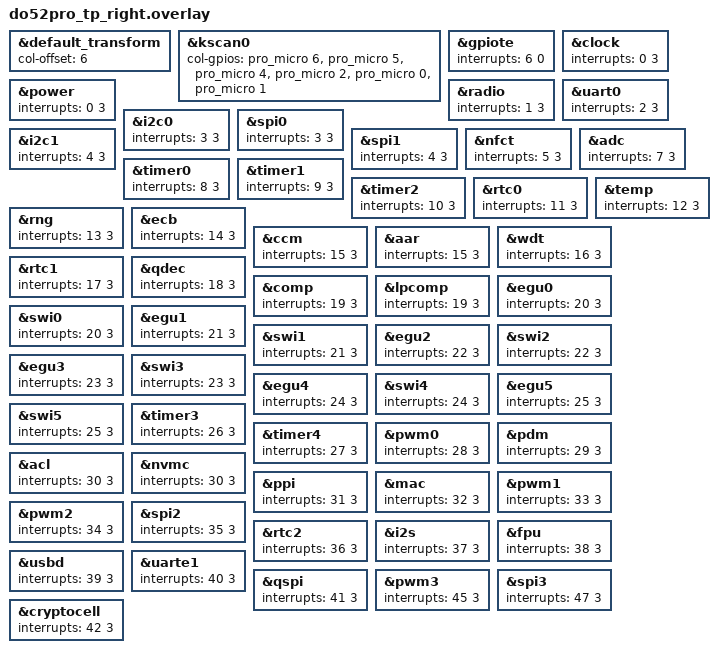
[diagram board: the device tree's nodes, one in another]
#include "do52pro_tp.dtsi"

&default_transform {
    col-offset = <6>;
};

&kscan0 {
    col-gpios
        = <&pro_micro 6 GPIO_ACTIVE_HIGH>
        , <&pro_micro 5 GPIO_ACTIVE_HIGH>
        , <&pro_micro 4 GPIO_ACTIVE_HIGH>
        , <&pro_micro 2 GPIO_ACTIVE_HIGH>
        , <&pro_micro 0 GPIO_ACTIVE_HIGH>
        , <&pro_micro 1 GPIO_ACTIVE_HIGH>
        ;
};

// 安定したUARTドライバーを有効化
#define MOUSE_PS2_DRIVER_UART

// SCL / SDA ピン設定
#define MOUSE_PS2_PIN_SCL_PRO_MICRO <&pro_micro 15 GPIO_ACTIVE_HIGH>
#define MOUSE_PS2_PIN_SDA_PRO_MICRO <&pro_micro 16 GPIO_ACTIVE_HIGH>
#define MOUSE_PS2_PIN_SDA_PINCTRL <NRF_PSEL(UART_RX, 0, 10)>

// リセット回路(2.2uF + 100kR)が基板上にあるため未接続のまま
// #define MOUSE_PS2_PIN_RST_PRO_MICRO <&pro_micro 9 GPIO_ACTIVE_HIGH>

// UARTボーレート設定
#define MOUSE_PS2_UART_BAUD_RATE <14400>

// nice!nano 未露出ピン設定（変更不要）
#define MOUSE_PS2_PIN_UNEXPOSED_TX <NRF_PSEL(UART_TX, 0, 27)>
#define MOUSE_PS2_PIN_UNEXPOSED_RX <NRF_PSEL(UART_RX, 0, 28)>

// 割り込み優先度設定（nice!nano v2用：これがないとUARTが動きません）
&gpiote {
    interrupts = < 6 0 >;
};

&clock {
    interrupts = < 0 3 >;
};

&power {
    interrupts = < 0 3 >;
};

&radio {
    interrupts = < 1 3 >;
};

&uart0 {
    interrupts = < 2 3 >;
};

&i2c0 {
    interrupts = < 3 3 >;
};

&spi0 {
    interrupts = < 3 3 >;
};

&i2c1 {
    interrupts = < 4 3 >;
};

&spi1 {
    interrupts = < 4 3 >;
};

&nfct {
    interrupts = < 5 3 >;
};

&adc {
    interrupts = < 7 3 >;
};

&timer0 {
    interrupts = < 8 3 >;
};

&timer1 {
    interrupts = < 9 3 >;
};

&timer2 {
    interrupts = < 10 3 >;
};

&rtc0 {
    interrupts = < 11 3 >;
};

&temp {
    interrupts = < 12 3 >;
};

&rng {
    interrupts = < 13 3 >;
};

&ecb {
    interrupts = < 14 3 >;
};

&ccm {
    interrupts = < 15 3 >;
};

&aar {
    interrupts = < 15 3 >;
};

&wdt {
    interrupts = < 16 3 >;
};

&rtc1 {
    interrupts = < 17 3 >;
};

&qdec {
    interrupts = < 18 3 >;
};

&comp {
    interrupts = < 19 3 >;
};

&lpcomp {
    interrupts = < 19 3 >;
};

&egu0 {
    interrupts = < 20 3 >;
};

&swi0 {
    interrupts = < 20 3 >;
};

&egu1 {
    interrupts = < 21 3 >;
};

&swi1 {
    interrupts = < 21 3 >;
};

&egu2 {
    interrupts = < 22 3 >;
};

&swi2 {
    interrupts = < 22 3 >;
};

&egu3 {
    interrupts = < 23 3 >;
};

&swi3 {
    interrupts = < 23 3 >;
};

&egu4 {
    interrupts = < 24 3 >;
};

&swi4 {
    interrupts = < 24 3 >;
};

&egu5 {
    interrupts = < 25 3 >;
};

&swi5 {
    interrupts = < 25 3 >;
};

&timer3 {
    interrupts = < 26 3 >;
};

&timer4 {
    interrupts = < 27 3 >;
};

&pwm0 {
    interrupts = < 28 3 >;
};

&pdm {
    interrupts = < 29 3 >;
};

&acl {
    interrupts = < 30 3 >;
};

&nvmc {
    interrupts = < 30 3 >;
};

&ppi {
    interrupts = < 31 3 >;
};

&mac {
    interrupts = < 32 3 >;
};

&pwm1 {
    interrupts = < 33 3 >;
};

&pwm2 {
    interrupts = < 34 3 >;
};

&spi2 {
    interrupts = < 35 3 >;
};

&rtc2 {
    interrupts = < 36 3 >;
};

&i2s {
    interrupts = < 37 3 >;
};

&fpu {
    interrupts = < 38 3 >;
};

&usbd {
    interrupts = < 39 3 >;
};

&uarte1 {
    interrupts = < 40 3 >;
};

&qspi {
    interrupts = < 41 3 >;
};

&pwm3 {
    interrupts = < 45 3 >;
};

&spi3 {
    interrupts = < 47 3 >;
};

&cryptocell {
    interrupts = < 42 3 >;
};
